# f28003x_clb_xbar_regs register map
Vendor: Texas Instruments
Peripheral module from a debugger description file (folder C2000).
Address unit: 16 bits
Registers are 32-bit, read-write, no defined reset value unless marked. A register's access mark holds for its fields unless they carry their own. Offsets are as the file gives them; lines under a group give offsets from that group; [hi:lo] are bit positions; {n}, {i} and the like mark numbered series; 'fields as' and 'values as' point back to an identical list; <NAME> marks a mode.

## CLB_XBAR_REGS — CLB XBAR Registers
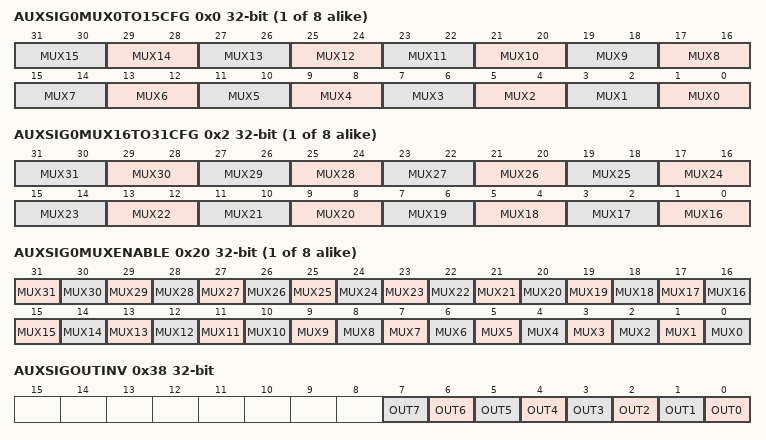
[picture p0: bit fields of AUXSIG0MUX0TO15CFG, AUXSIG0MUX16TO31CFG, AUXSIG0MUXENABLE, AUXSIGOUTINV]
{0x0+4i} AUXSIG{i}MUX0TO15CFG (i=0..7) — CLB XBAR Mux Configuration for Output-{i}
  [2n+1:2n] MUX{n} (n=0..15) — MUX{n} Configuration for AUXSIG{i} of CLB-XBAR
{0x2+4i} AUXSIG{i}MUX16TO31CFG (i=0..7) — CLB XBAR Mux Configuration for Output-{i}
  [2n-31:2n-32] MUX{n} (n=16..31) — MUX{n} Configuration for AUXSIG{i} of CLB-XBAR
{0x20+2i} AUXSIG{i}MUXENABLE (i=0..7) — CLB XBAR Mux Enable Register for Output-{i}
  [n] MUX{n} (n=1..31) — MUX{n} to drive AUXSIG{i} of CLB-XBAR
  [0] MUX0 — mux0 to drive AUXSIG{i} of CLB-XBAR
0x38 AUXSIGOUTINV — CLB XBAR Output Inversion Register
  [n] OUT{n} (n=0..7) — Selects polarity for AUXSIG{n} of CLB-XBAR
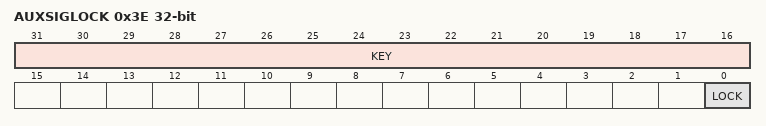
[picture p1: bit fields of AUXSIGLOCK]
0x3E AUXSIGLOCK — ClbXbar Configuration Lock register
  [31:16] KEY — Write Protection KEY
  [0] LOCK — Locks the configuration for CLB-XBAR
